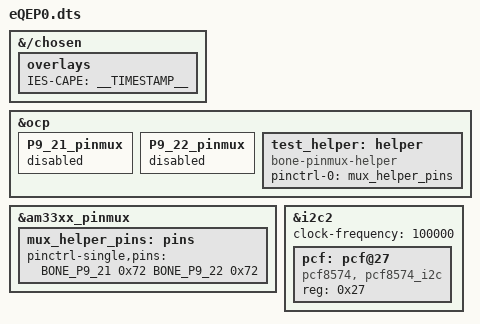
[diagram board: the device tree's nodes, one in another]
/dts-v1/;
/plugin/;

#include <dt-bindings/board/am335x-bbw-bbb-base.h>
#include <dt-bindings/pinctrl/am33xx.h>

/*
 * Helper to show loaded overlays under: /proc/device-tree/chosen/overlays/
 */
&{/chosen} {
	overlays {
		IES-CAPE = __TIMESTAMP__;
	};
};

/*
 * Free up the pins used by the cape from the pinmux helpers.
 */
&ocp {
	P9_21_pinmux { status = "disabled"; };	/* P9_21: spi0_d0 */
	P9_22_pinmux { status = "disabled"; };	/* P9_22: spi0_sclk */
};

&am33xx_pinmux {
	mux_helper_pins: pins {
		pinctrl-single,pins = <
			BONE_P9_21 0x72	/* spi0_d0, INPUT MODE0 */
			BONE_P9_22 0x72	/* spi0_sclk, INPUT MODE0 */

		>;
	};
};

&ocp {
	test_helper: helper {
		compatible = "bone-pinmux-helper";
		pinctrl-names = "default";
		pinctrl-0 = <&mux_helper_pins>;
		status = "okay";
	};
};



&i2c2  {
	status = "okay";

	/* this is the configuration part */
	clock-frequency = <100000>; // Standard speed for testing.

	#address-cells = <1>;
	#size-cells = <0>;
     pcf:pcf@27 {

          compatible = "pcf8574, pcf8574_i2c";
          reg = <0x27>;
     };
};

